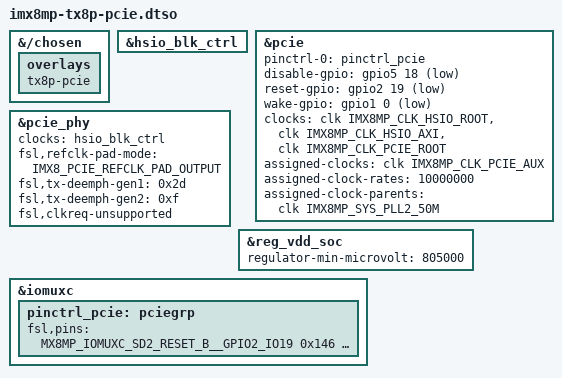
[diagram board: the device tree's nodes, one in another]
// SPDX-License-Identifier: (GPL-2.0 OR MIT)
/*
 * Copyright 2024 Markus Bauer <MB@KARO-electronics.de>
 *
 */

/dts-v1/;
/plugin/;

#include <dt-bindings/phy/phy-imx8-pcie.h>
#include <dt-bindings/clock/imx8mp-clock.h>
#include <dt-bindings/gpio/gpio.h>
#include "imx8mp-pinfunc.h"

&{/chosen} {
	overlays {
		tx8p-pcie;
	};
};

&hsio_blk_ctrl {
	#clock-cells = <0>;
};

&pcie {
	pinctrl-names = "default";
	pinctrl-0 = <&pinctrl_pcie>;
	disable-gpio = <&gpio5 18 GPIO_ACTIVE_LOW>;
	reset-gpio = <&gpio2 19 GPIO_ACTIVE_LOW>;
	wake-gpio = <&gpio1 0 GPIO_ACTIVE_LOW>;
	clocks = <&clk IMX8MP_CLK_HSIO_ROOT>,
		 <&clk IMX8MP_CLK_HSIO_AXI>,
		 <&clk IMX8MP_CLK_PCIE_ROOT>;
	clock-names = "pcie", "pcie_bus", "pcie_aux";
	assigned-clocks = <&clk IMX8MP_CLK_PCIE_AUX>;
	assigned-clock-rates = <10000000>;
	assigned-clock-parents = <&clk IMX8MP_SYS_PLL2_50M>;
	status = "okay";
};

&pcie_phy {
	clocks = <&hsio_blk_ctrl>;
	clock-names = "ref";
	fsl,refclk-pad-mode = <IMX8_PCIE_REFCLK_PAD_OUTPUT>;
	fsl,tx-deemph-gen1 = <0x2d>;
	fsl,tx-deemph-gen2 = <0xf>;
	fsl,clkreq-unsupported;
	status = "okay";
};

&reg_vdd_soc {
	/* PCIe requires a minimum vdd soc voltage of 0.805V */
	regulator-min-microvolt = <805000>;
};

&iomuxc {
	pinctrl_pcie: pciegrp {
		fsl,pins = <
			MX8MP_IOMUXC_SD2_RESET_B__GPIO2_IO19	0x146
			MX8MP_IOMUXC_GPIO1_IO00__GPIO1_IO00	0x146
			MX8MP_IOMUXC_I2C3_SCL__GPIO5_IO18	0x146
		>;
	};
};
